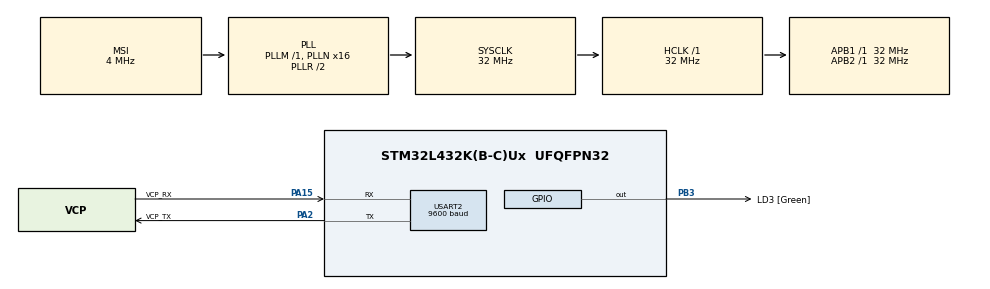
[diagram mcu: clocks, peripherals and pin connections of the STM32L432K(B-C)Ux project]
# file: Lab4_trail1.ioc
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Mcu.Family=STM32L4
Mcu.Name=STM32L432K(B-C)Ux
Mcu.Package=UFQFPN32
NVIC.PriorityGroup=NVIC_PRIORITYGROUP_4
NVIC.RTC_Alarm_IRQn=true\:0\:0\:false\:false\:true\:true\:true\:true
NVIC.USART2_IRQn=true\:0\:0\:false\:false\:true\:true\:true\:true
PA0.GPIO_Label=MCO [High speed clock in]
PA0.Mode=HSE-External-Clock-Source-for-LittleOrca
PA0.Signal=RCC_CK_IN
PA13\ (JTMS-SWDIO).GPIO_Label=SWDIO
PA13\ (JTMS-SWDIO).Mode=Serial_Wire
PA13\ (JTMS-SWDIO).Signal=SYS_JTMS-SWDIO
PA14\ (JTCK-SWCLK).GPIO_Label=SWCLK
PA14\ (JTCK-SWCLK).Mode=Serial_Wire
PA14\ (JTCK-SWCLK).Signal=SYS_JTCK-SWCLK
PA15\ (JTDI).GPIO_Label=VCP_RX
PA15\ (JTDI).Mode=Asynchronous
PA15\ (JTDI).Signal=USART2_RX
PA2.GPIO_Label=VCP_TX
PA2.Mode=Asynchronous
PA2.Signal=USART2_TX
PB3\ (JTDO-TRACESWO).GPIO_Label=LD3 [Green]
PB3\ (JTDO-TRACESWO).Signal=GPIO_Output
PC14-OSC32_IN\ (PC14).Mode=LSE-External-Oscillator
PC14-OSC32_IN\ (PC14).Signal=RCC_OSC32_IN
PC15-OSC32_OUT\ (PC15).Mode=LSE-External-Oscillator
PC15-OSC32_OUT\ (PC15).Signal=RCC_OSC32_OUT
ProjectManager.HeapSize=0x200
ProjectManager.StackSize=0x400
ProjectManager.TargetToolchain=STM32CubeIDE
RCC.AHBFreq_Value=32000000
RCC.APB1Freq_Value=32000000
RCC.APB1TimFreq_Value=32000000
RCC.APB2Freq_Value=32000000
RCC.APB2TimFreq_Value=32000000
RCC.CortexFreq_Value=32000000
RCC.HCLKFreq_Value=32000000
RCC.HSE_VALUE=8000000
RCC.HSI16_VALUE=16000000
RCC.HSI48_VALUE=48000000
RCC.HSI_VALUE=16000000
RCC.MSI_VALUE=4000000
RCC.PLLMUL=RCC_PLLMUL_4
RCC.PLLN=16
RCC.SYSCLKFreq_VALUE=32000000
RCC.SYSCLKSource=RCC_SYSCLKSOURCE_PLLCLK
RCC.VCOOutputFreq_Value=64000000
RTC.Alarm=RTC_ALARM_A
RTC.AlarmMaskDateWeekDay=RTC_ALARMMASK_DATEWEEKDAY
RTC.AlarmMaskHours=RTC_ALARMMASK_HOURS
RTC.AlarmMaskMinutes=RTC_ALARMMASK_MINUTES
RTC.Date=10
RTC.Format=RTC_FORMAT_BIN
RTC.Hours=14
RTC.Minutes=21
RTC.Month=RTC_MONTH_FEBRUARY
RTC.Seconds_A=30
RTC.Year=23
USART2.BaudRate=9600
USART2.VirtualMode-Asynchronous=VM_ASYNC
VP_RTC_VS_RTC_Activate.Mode=RTC_Enabled
VP_RTC_VS_RTC_Alarm_A_Intern.Mode=Alarm A
VP_RTC_VS_RTC_Calendar.Mode=RTC_Calendar
board=NUCLEO-L432KC

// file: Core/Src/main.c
/* USER CODE BEGIN Header */
/**
  ******************************************************************************
  * @file           : main.c
  * @brief          : Main program body
  ******************************************************************************
  * @attention
  *
  * Copyright (c) 2023 STMicroelectronics.
  * All rights reserved.
  *
  * This software is licensed under terms that can be found in the LICENSE file
  * in the root directory of this software component.
  * If no LICENSE file comes with this software, it is provided AS-IS.
  *
  ******************************************************************************
  */
/* USER CODE END Header */
#include "main.h"

/* USER CODE BEGIN Includes */
#include <retarget.h>
#include <stdio.h>
#include <string.h>
#include <stm32l4xx_ll_usart.h>
#include <queue.h>
#include <led.h>
#include <command.h>
/* USER CODE END Includes */

RTC_HandleTypeDef hrtc;

UART_HandleTypeDef huart2;

/* USER CODE BEGIN PV */
queue_t rx_queue;
volatile int alarm_flag = 0;

/* USER CODE END PV */

void SystemClock_Config(void);
static void MX_GPIO_Init(void);
static void MX_USART2_UART_Init(void);
static void MX_RTC_Init(void);

int main(void)
{
  /* USER CODE BEGIN 1 */
	uint8_t command[MAX_COMMAND_LEN];
	  int command_length = 0;
  /* USER CODE END 1 */

  /* MCU Configuration--------------------------------------------------------*/

  /* Reset of all peripherals, Initializes the Flash interface and the Systick. */
  HAL_Init();

  /* USER CODE BEGIN Init */
  init_queue(&rx_queue);
  /* USER CODE END Init */

  /* Configure the system clock */
  SystemClock_Config();

  /* Initialize all configured peripherals */
  MX_GPIO_Init();
  MX_USART2_UART_Init();
  MX_RTC_Init();
  /* USER CODE BEGIN 2 */
  RetargetInit(&huart2);
  LL_USART_EnableIT_RXNE(USART2); // Turn the the usart2 interrupt
  printf("\n\rSystem Up and Running\n\r");
  /* USER CODE END 2 */

  /* Infinite loop */
  while (1)
  {

    /* USER CODE BEGIN 3 */
	    // Command Interpreter
	    if (get_command(command)) {
	      command_length = delspace(command);
	      if (command_length != -1) {
	        if(execute_command(command)) {
	          printf("NOK\n\r");
	          prompt();
	        }
	        else {
	          prompt();
	        }
	      }
	      else {
	        printf("NOK\n\r");
	        prompt();
	      }

	    }
	    if (alarm_flag) {
	      printf("Alarm happened\n\r");
	      alarm_flag = 0;
	      lon();
	      HAL_Delay(100);
	      lof();
	    }

  }
  /* USER CODE END 3 */
}

void SystemClock_Config(void)
{
  RCC_OscInitTypeDef RCC_OscInitStruct = {0};
  RCC_ClkInitTypeDef RCC_ClkInitStruct = {0};

  /** Configure the main internal regulator output voltage
  */
  if (HAL_PWREx_ControlVoltageScaling(PWR_REGULATOR_VOLTAGE_SCALE1) != HAL_OK)
  {
    Error_Handler();
  }

  /** Configure LSE Drive Capability
  */
  HAL_PWR_EnableBkUpAccess();
  __HAL_RCC_LSEDRIVE_CONFIG(RCC_LSEDRIVE_LOW);

  /** Initializes the RCC Oscillators according to the specified parameters
  * in the RCC_OscInitTypeDef structure.
  */
  RCC_OscInitStruct.OscillatorType = RCC_OSCILLATORTYPE_LSI|RCC_OSCILLATORTYPE_LSE
                              |RCC_OSCILLATORTYPE_MSI;
  RCC_OscInitStruct.LSEState = RCC_LSE_ON;
  RCC_OscInitStruct.LSIState = RCC_LSI_ON;
  RCC_OscInitStruct.MSIState = RCC_MSI_ON;
  RCC_OscInitStruct.MSICalibrationValue = 0;
  RCC_OscInitStruct.MSIClockRange = RCC_MSIRANGE_6;
  RCC_OscInitStruct.PLL.PLLState = RCC_PLL_ON;
  RCC_OscInitStruct.PLL.PLLSource = RCC_PLLSOURCE_MSI;
  RCC_OscInitStruct.PLL.PLLM = 1;
  RCC_OscInitStruct.PLL.PLLN = 16;
  RCC_OscInitStruct.PLL.PLLP = RCC_PLLP_DIV7;
  RCC_OscInitStruct.PLL.PLLQ = RCC_PLLQ_DIV2;
  RCC_OscInitStruct.PLL.PLLR = RCC_PLLR_DIV2;
  if (HAL_RCC_OscConfig(&RCC_OscInitStruct) != HAL_OK)
  {
    Error_Handler();
  }

  /** Initializes the CPU, AHB and APB buses clocks
  */
  RCC_ClkInitStruct.ClockType = RCC_CLOCKTYPE_HCLK|RCC_CLOCKTYPE_SYSCLK
                              |RCC_CLOCKTYPE_PCLK1|RCC_CLOCKTYPE_PCLK2;
  RCC_ClkInitStruct.SYSCLKSource = RCC_SYSCLKSOURCE_PLLCLK;
  RCC_ClkInitStruct.AHBCLKDivider = RCC_SYSCLK_DIV1;
  RCC_ClkInitStruct.APB1CLKDivider = RCC_HCLK_DIV1;
  RCC_ClkInitStruct.APB2CLKDivider = RCC_HCLK_DIV1;

  if (HAL_RCC_ClockConfig(&RCC_ClkInitStruct, FLASH_LATENCY_1) != HAL_OK)
  {
    Error_Handler();
  }

  /** Enable MSI Auto calibration
  */
  HAL_RCCEx_EnableMSIPLLMode();
}

static void MX_RTC_Init(void)
{

  RTC_TimeTypeDef sTime = {0};
  RTC_DateTypeDef sDate = {0};
  RTC_AlarmTypeDef sAlarm = {0};

  /** Initialize RTC Only
  */
  hrtc.Instance = RTC;
  hrtc.Init.HourFormat = RTC_HOURFORMAT_24;
  hrtc.Init.AsynchPrediv = 127;
  hrtc.Init.SynchPrediv = 255;
  hrtc.Init.OutPut = RTC_OUTPUT_DISABLE;
  hrtc.Init.OutPutRemap = RTC_OUTPUT_REMAP_NONE;
  hrtc.Init.OutPutPolarity = RTC_OUTPUT_POLARITY_HIGH;
  hrtc.Init.OutPutType = RTC_OUTPUT_TYPE_OPENDRAIN;
  if (HAL_RTC_Init(&hrtc) != HAL_OK)
  {
    Error_Handler();
  }

  /** Initialize RTC and set the Time and Date
  */
  sTime.Hours = 14;
  sTime.Minutes = 21;
  sTime.Seconds = 0;
  sTime.DayLightSaving = RTC_DAYLIGHTSAVING_NONE;
  sTime.StoreOperation = RTC_STOREOPERATION_RESET;
  if (HAL_RTC_SetTime(&hrtc, &sTime, RTC_FORMAT_BIN) != HAL_OK)
  {
    Error_Handler();
  }
  sDate.WeekDay = RTC_WEEKDAY_MONDAY;
  sDate.Month = RTC_MONTH_FEBRUARY;
  sDate.Date = 10;
  sDate.Year = 23;

  if (HAL_RTC_SetDate(&hrtc, &sDate, RTC_FORMAT_BIN) != HAL_OK)
  {
    Error_Handler();
  }

  /** Enable the Alarm A
  */
  sAlarm.AlarmTime.Hours = 0;
  sAlarm.AlarmTime.Minutes = 0;
  sAlarm.AlarmTime.Seconds = 30;
  sAlarm.AlarmTime.SubSeconds = 0;
  sAlarm.AlarmTime.DayLightSaving = RTC_DAYLIGHTSAVING_NONE;
  sAlarm.AlarmTime.StoreOperation = RTC_STOREOPERATION_RESET;
  sAlarm.AlarmMask = RTC_ALARMMASK_DATEWEEKDAY|RTC_ALARMMASK_HOURS
                              |RTC_ALARMMASK_MINUTES;
  sAlarm.AlarmSubSecondMask = RTC_ALARMSUBSECONDMASK_ALL;
  sAlarm.AlarmDateWeekDaySel = RTC_ALARMDATEWEEKDAYSEL_DATE;
  sAlarm.AlarmDateWeekDay = 1;
  sAlarm.Alarm = RTC_ALARM_A;
  if (HAL_RTC_SetAlarm_IT(&hrtc, &sAlarm, RTC_FORMAT_BIN) != HAL_OK)
  {
    Error_Handler();
  }

}

static void MX_USART2_UART_Init(void)
{

  huart2.Instance = USART2;
  huart2.Init.BaudRate = 9600;
  huart2.Init.WordLength = UART_WORDLENGTH_8B;
  huart2.Init.StopBits = UART_STOPBITS_1;
  huart2.Init.Parity = UART_PARITY_NONE;
  huart2.Init.Mode = UART_MODE_TX_RX;
  huart2.Init.HwFlowCtl = UART_HWCONTROL_NONE;
  huart2.Init.OverSampling = UART_OVERSAMPLING_16;
  huart2.Init.OneBitSampling = UART_ONE_BIT_SAMPLE_DISABLE;
  huart2.AdvancedInit.AdvFeatureInit = UART_ADVFEATURE_NO_INIT;
  if (HAL_UART_Init(&huart2) != HAL_OK)
  {
    Error_Handler();
  }
  /* USER CODE BEGIN USART2_Init 2 */
  LL_USART_EnableIT_RXNE(USART2);
  /* USER CODE END USART2_Init 2 */

}

static void MX_GPIO_Init(void)
{
  GPIO_InitTypeDef GPIO_InitStruct = {0};

  /* GPIO Ports Clock Enable */
  __HAL_RCC_GPIOC_CLK_ENABLE();
  __HAL_RCC_GPIOA_CLK_ENABLE();
  __HAL_RCC_GPIOB_CLK_ENABLE();

  /*Configure GPIO pin Output Level */
  HAL_GPIO_WritePin(LD3_GPIO_Port, LD3_Pin, GPIO_PIN_RESET);

  /*Configure GPIO pin : LD3_Pin */
  GPIO_InitStruct.Pin = LD3_Pin;
  GPIO_InitStruct.Mode = GPIO_MODE_OUTPUT_PP;
  GPIO_InitStruct.Pull = GPIO_NOPULL;
  GPIO_InitStruct.Speed = GPIO_SPEED_FREQ_LOW;
  HAL_GPIO_Init(LD3_GPIO_Port, &GPIO_InitStruct);

}

void Error_Handler(void)
{
  __disable_irq();
  while (1)
  {
  }
}
